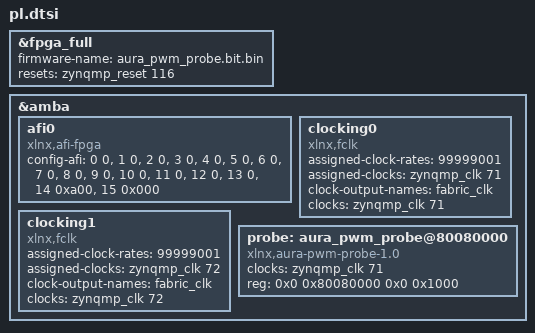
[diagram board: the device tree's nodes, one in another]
/*
 * CAUTION: This file is automatically generated by Xilinx.
 * Version: XSCT 2022.2
 * Today is: Sun Oct  4 22:02:18 2026
 */


/dts-v1/;
/plugin/;
/ {
	fragment@0 {
		target = <&fpga_full>;
		overlay0: __overlay__ {
			#address-cells = <2>;
			#size-cells = <2>;
			firmware-name = "aura_pwm_probe.bit.bin";
			resets = <&zynqmp_reset 116>;
		};
	};
	fragment@1 {
		target = <&amba>;
		overlay1: __overlay__ {
			afi0: afi0 {
				compatible = "xlnx,afi-fpga";
				config-afi = < 0 0>, <1 0>, <2 0>, <3 0>, <4 0>, <5 0>, <6 0>, <7 0>, <8 0>, <9 0>, <10 0>, <11 0>, <12 0>, <13 0>, <14 0xa00>, <15 0x000>;
			};
			clocking0: clocking0 {
				#clock-cells = <0>;
				assigned-clock-rates = <99999001>;
				assigned-clocks = <&zynqmp_clk 71>;
				clock-output-names = "fabric_clk";
				clocks = <&zynqmp_clk 71>;
				compatible = "xlnx,fclk";
			};
			clocking1: clocking1 {
				#clock-cells = <0>;
				assigned-clock-rates = <99999001>;
				assigned-clocks = <&zynqmp_clk 72>;
				clock-output-names = "fabric_clk";
				clocks = <&zynqmp_clk 72>;
				compatible = "xlnx,fclk";
			};
		};
	};
	fragment@2 {
		target = <&amba>;
		overlay2: __overlay__ {
			#address-cells = <2>;
			#size-cells = <2>;
			probe: aura_pwm_probe@80080000 {
				/* This is a place holder node for a custom IP, user may need to update the entries */
				clock-names = "s_axi_aclk";
				clocks = <&zynqmp_clk 71>;
				compatible = "xlnx,aura-pwm-probe-1.0";
				reg = <0x0 0x80080000 0x0 0x1000>;
			};
		};
	};
};
